# N32H7xx register map
Vendor: Nationstech Ltd.; File version: 1.0
Registers are 32-bit, read-write, reset 0x0 unless marked. A register's access mark holds for its fields unless they carry their own. Offsets are from the block's base; [hi:lo] are bit positions; {n}, {i} and the like mark numbered series; 'fields as' and 'values as' point back to an identical list.

## CORDIC — CORDIC Processors
Base 0x400F1000
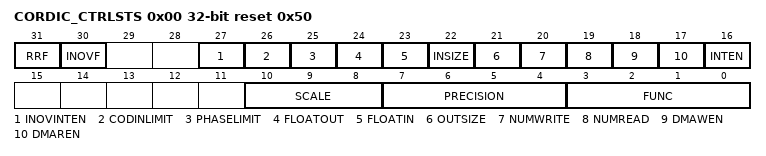
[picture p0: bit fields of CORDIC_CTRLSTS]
0x00 CORDIC_CTRLSTS reset 0x50 — CORDIC Control Status Register
  [31] RRF ro — Result Ready Flag
  [30] INOVF — Input Overflow Flag
  [27] INOVINTEN — Input Overflow Interrupt Control Bit
  [26] CODINLIMIT — Coordinate Output Limit Control
  [25] PHASELIMIT — Phase Output Limit Control
  [24] FLOATOUT — Floating-point Fixed-point Output Control
  [23] FLOATIN — Floating-point Fixed-point Input Control.
  [22] INSIZE — Input Data Width
  [21] OUTSIZE — Output Data Width
  [20] NUMWRITE — CORDIC_WDAT Register Parameter Count
  [19] NUMREAD — Number of results that can be read from the CORDIC_RDAT register
  [18] DMAWEN — DMA Write Request Enable
  [17] DMAREN — DMA Read Request Enable
  [16] INTEN — Interrupt Enable
  [10:8] SCALE — Scaling Factor
  [7:4] PRECISION — Iteration Count
  [3:0] FUNC — Functions
0x04 CORDIC_WDAT wo — CORDIC Write Data Register
  [31:0] WDAT — Write Data
0x08 CORDIC_RDAT ro — CORDIC Read Data Register
  [31:0] RDAT — Read Data

## USB_HS1_Global — USB high speed dual role 1
Base 0x40100000
Same registers: USB_HS2_Global 0x40060000
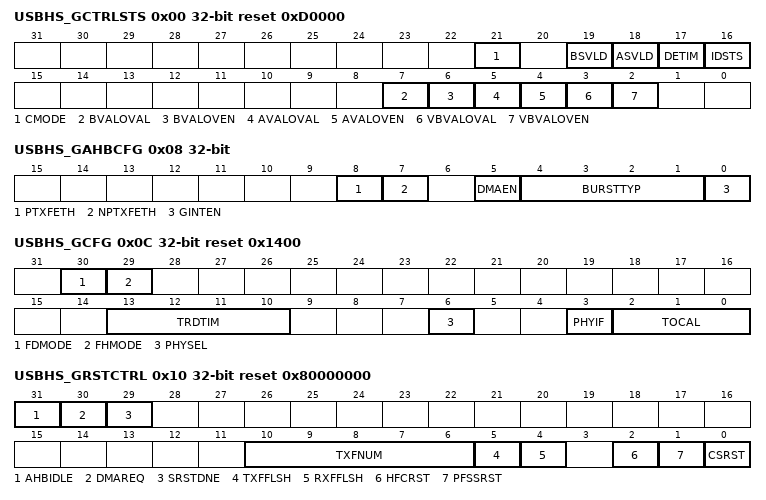
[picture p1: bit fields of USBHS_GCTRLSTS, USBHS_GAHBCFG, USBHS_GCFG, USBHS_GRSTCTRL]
0x00 USBHS_GCTRLSTS reset 0xD0000 — USBHS global control and status register
  [21] CMODE ro, [19] BSVLD ro, [18] ASVLD ro, [17] DETIM ro, [16] IDSTS ro, [7] BVALOVAL, [6] BVALOVEN, [5] AVALOVAL, [4] AVALOVEN, [3] VBVALOVAL, [2] VBVALOVEN
0x08 USBHS_GAHBCFG
  [8] PTXFETH, [7] NPTXFETH, [5] DMAEN, [4:1] BURSTTYP, [0] GINTEN
0x0C USBHS_GCFG reset 0x1400
  [30] FDMODE, [29] FHMODE, [13:10] TRDTIM, [6] PHYSEL, [3] PHYIF wo, [2:0] TOCAL
0x10 USBHS_GRSTCTRL reset 0x80000000
  [31] AHBIDLE ro, [30] DMAREQ ro, [29] SRSTDNE ro, [10:6] TXFNUM, [5] TXFFLSH, [4] RXFFLSH, [2] HFCRST, [1] PFSSRST, [0] CSRST
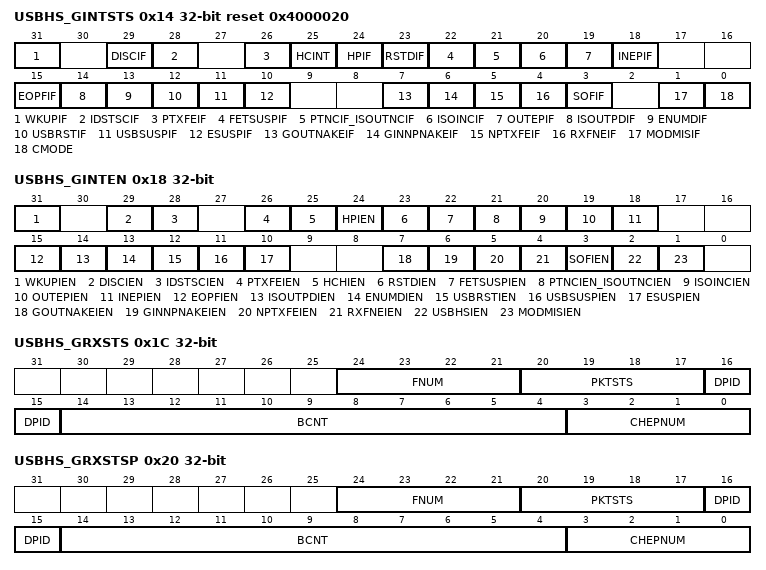
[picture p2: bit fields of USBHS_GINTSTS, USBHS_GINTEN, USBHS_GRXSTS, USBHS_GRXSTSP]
0x14 USBHS_GINTSTS reset 0x4000020
  [31] WKUPIF
  [29] DISCIF
  [28] IDSTSCIF
  [26] PTXFEIF ro
  [25] HCINT ro — Host channels interrupt
  [24] HPIF ro
  [23] RSTDIF
  [22] FETSUSPIF
  [21] PTNCIF_ISOUTNCIF
  [20] ISOINCIF
  [19] OUTEPIF ro
  [18] INEPIF ro
  [15] EOPFIF
  [14] ISOUTPDIF
  [13] ENUMDIF
  [12] USBRSTIF
  [11] USBSUSPIF
  [10] ESUSPIF
  [7] GOUTNAKEIF ro
  [6] GINNPNAKEIF ro
  [5] NPTXFEIF ro
  [4] RXFNEIF ro
  [3] SOFIF
  [1] MODMISIF
  [0] CMODE ro
0x18 USBHS_GINTEN
  [31] WKUPIEN, [29] DISCIEN, [28] IDSTSCIEN, [26] PTXFEIEN, [25] HCHIEN, [24] HPIEN, [23] RSTDIEN, [22] FETSUSPIEN, [21] PTNCIEN_ISOUTNCIEN, [20] ISOINCIEN, [19] OUTEPIEN, [18] INEPIEN, [15] EOPFIEN, [14] ISOUTPDIEN, [13] ENUMDIEN, [12] USBRSTIEN, [11] USBSUSPIEN, [10] ESUSPIEN, [7] GOUTNAKEIEN, [6] GINNPNAKEIEN, [5] NPTXFEIEN, [4] RXFNEIEN, [3] SOFIEN, [2] USBHSIEN, [1] MODMISIEN
0x1C USBHS_GRXSTS ro
  [24:21] FNUM, [20:17] PKTSTS, [16:15] DPID, [14:4] BCNT, [3:0] CHEPNUM
0x20 USBHS_GRXSTSP ro
  fields as USBHS_GRXSTS
0x24 USBHS_GRXFSIZ reset 0x200
  [10:0] RXFDEP
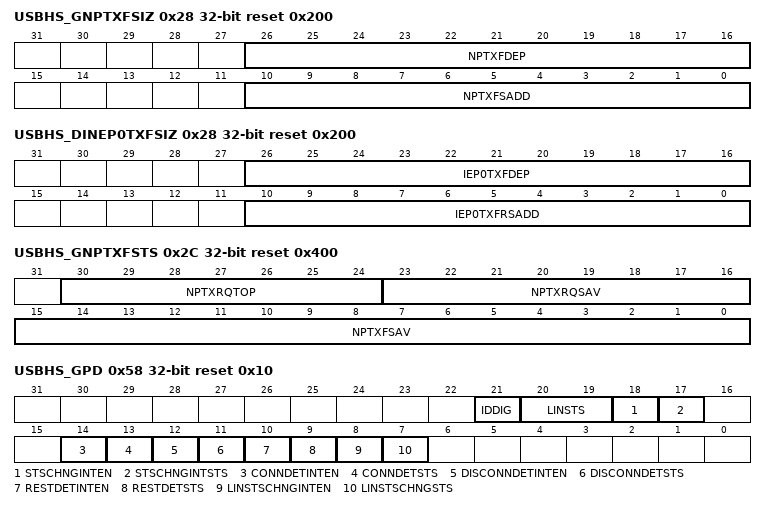
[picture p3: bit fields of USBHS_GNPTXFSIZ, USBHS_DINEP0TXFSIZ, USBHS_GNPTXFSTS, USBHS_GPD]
0x28 USBHS_GNPTXFSIZ reset 0x200
  [26:16] NPTXFDEP
  [10:0] NPTXFSADD — NNPTXFSADD
0x28 USBHS_DINEP0TXFSIZ reset 0x200 (alternate view of USBHS_GNPTXFSIZ) — EUSBHS_DINEP0TXFSIZ
  [26:16] IEP0TXFDEP, [10:0] IEP0TXFRSADD
0x2C USBHS_GNPTXFSTS ro reset 0x400
  [30:24] NPTXRQTOP, [23:16] NPTXRQSAV, [15:0] NPTXFSAV
0x3C USBHS_CID reset 0x3608
0x58 USBHS_GPD reset 0x10
  [21] IDDIG, [20:19] LINSTS, [18] STSCHNGINTEN, [17] STSCHNGINTSTS, [14] CONNDETINTEN, [13] CONNDETSTS, [12] DISCONNDETINTEN, [11] DISCONNDETSTS, [10] RESTDETINTEN, [9] RESTDETSTS, [8] LINSTSCHNGINTEN, [7] LINSTSCHNGSTS
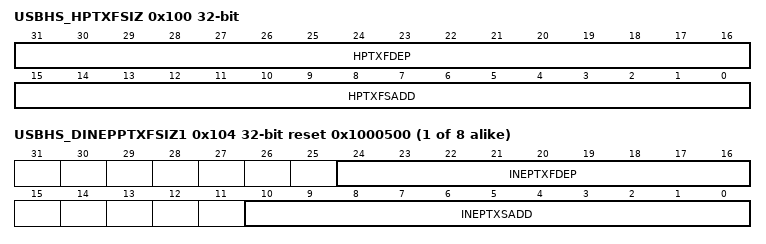
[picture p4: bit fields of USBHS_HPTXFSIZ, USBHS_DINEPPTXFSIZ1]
0x100 USBHS_HPTXFSIZ
  [31:16] HPTXFDEP, [15:0] HPTXFSADD
{0x100+4i} USBHS_DINEPPTXFSIZ{i} reset 0x1000500 (i=1..8)
  [24:16] INEPTXFDEP, [10:0] INEPTXSADD

## USB_HS1_HOST — USB high speed host mode 1
Base 0x40100400
Same registers: USB_HS2_HOST 0x40060400
0x00 USBHS_HCFG
  [2] SPSEL
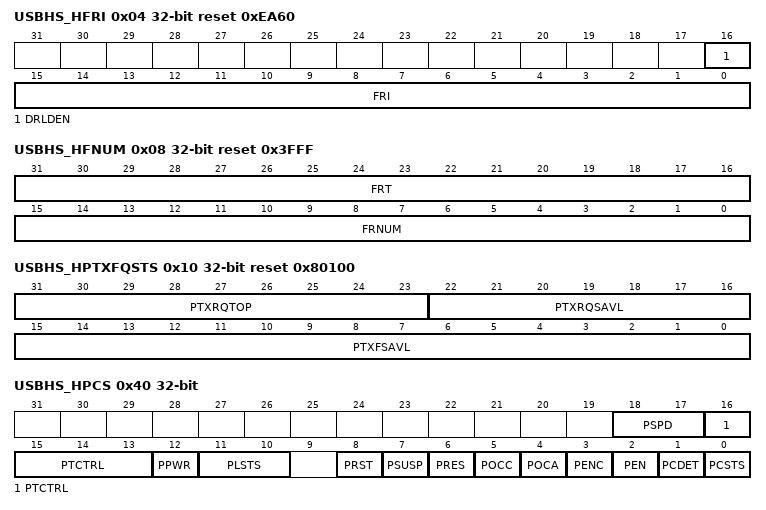
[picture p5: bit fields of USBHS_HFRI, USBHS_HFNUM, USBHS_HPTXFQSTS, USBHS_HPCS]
0x04 USBHS_HFRI reset 0xEA60
  [16] DRLDEN, [15:0] FRI
0x08 USBHS_HFNUM ro reset 0x3FFF
  [31:16] FRT, [15:0] FRNUM
0x10 USBHS_HPTXFQSTS reset 0x80100
  [31:23] PTXRQTOP ro, [22:16] PTXRQSAVL ro, [15:0] PTXFSAVL
0x14 USBHS_HACHINT ro
  [15:0] HACHINT
0x18 USBHS_HACHINTEN
  [15:0] HACHINTEN
0x40 USBHS_HPCS
  [18:17] PSPD ro, [16:13] PTCTRL, [12] PPWR, [11:10] PLSTS ro, [8] PRST, [7] PSUSP, [6] PRES, [5] POCC, [4] POCA ro, [3] PENC, [2] PEN, [1] PCDET, [0] PCSTS ro
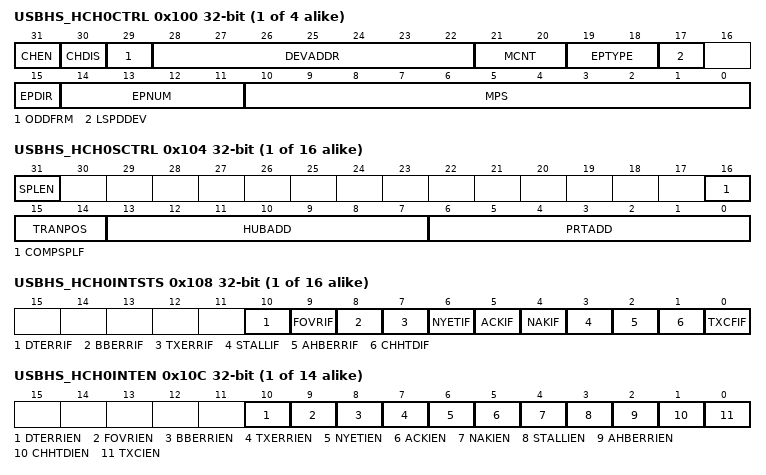
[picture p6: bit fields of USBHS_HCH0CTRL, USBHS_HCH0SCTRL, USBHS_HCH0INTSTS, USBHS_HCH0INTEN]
{0x100+0x20*i} USBHS_HCH{i}CTRL (i=0..3)
  [31] CHEN, [30] CHDIS, [29] ODDFRM, [28:22] DEVADDR, [21:20] MCNT, [19:18] EPTYPE, [17] LSPDDEV, [15] EPDIR, [14:11] EPNUM, [10:0] MPS
{0x104+0x20*i} USBHS_HCH{i}SCTRL (i=0..15)
  [31] SPLEN, [16] COMPSPLF, [15:14] TRANPOS, [13:7] HUBADD, [6:0] PRTADD
{0x108+0x20*i} USBHS_HCH{i}INTSTS (i=0..15)
  [10] DTERRIF, [9] FOVRIF, [8] BBERRIF, [7] TXERRIF, [6] NYETIF, [5] ACKIF, [4] NAKIF, [3] STALLIF, [2] AHBERRIF, [1] CHHTDIF, [0] TXCFIF
{0x10C+0x20*i} USBHS_HCH{i}INTEN (i=0..13)
  [10] DTERRIEN, [9] FOVRIEN, [8] BBERRIEN, [7] TXERRIEN, [6] NYETIEN, [5] ACKIEN, [4] NAKIEN, [3] STALLIEN, [2] AHBERRIEN, [1] CHHTDIEN, [0] TXCIEN
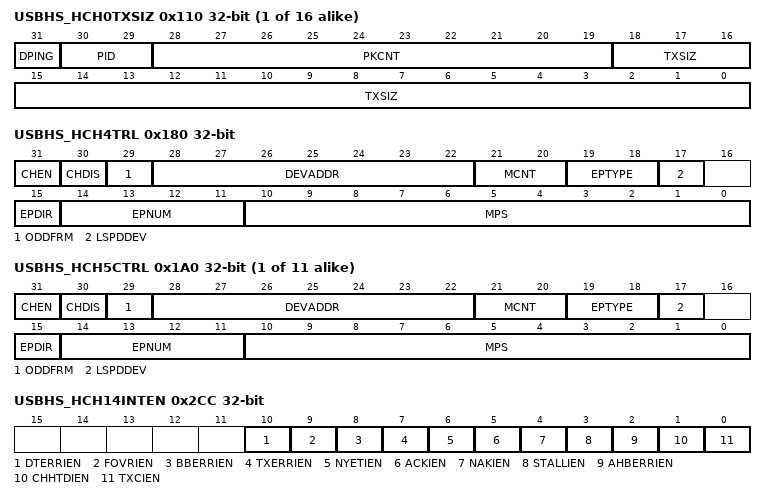
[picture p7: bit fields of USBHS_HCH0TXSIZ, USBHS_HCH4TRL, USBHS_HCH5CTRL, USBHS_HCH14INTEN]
{0x110+0x20*i} USBHS_HCH{i}TXSIZ (i=0..15)
  [31] DPING, [30:29] PID, [28:19] PKCNT, [18:0] TXSIZ
{0x114+0x20*i} USBHS_HCH{i}DMADD (i=0..15)
  [31:0] DMADD
0x180 USBHS_HCH4TRL — USBHS_HCH4CTRL
  fields as USBHS_HCH0CTRL
{0x100+0x20*i} USBHS_HCH{i}CTRL (i=5..15)
  fields as USBHS_HCH0CTRL
0x2CC USBHS_HCH14INTEN — USBHS_HCH14NTEN
  fields as USBHS_HCH0INTEN
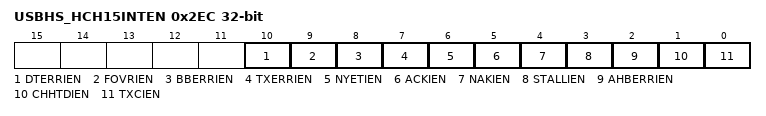
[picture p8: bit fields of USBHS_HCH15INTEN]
0x2EC USBHS_HCH15INTEN
  fields as USBHS_HCH0INTEN
